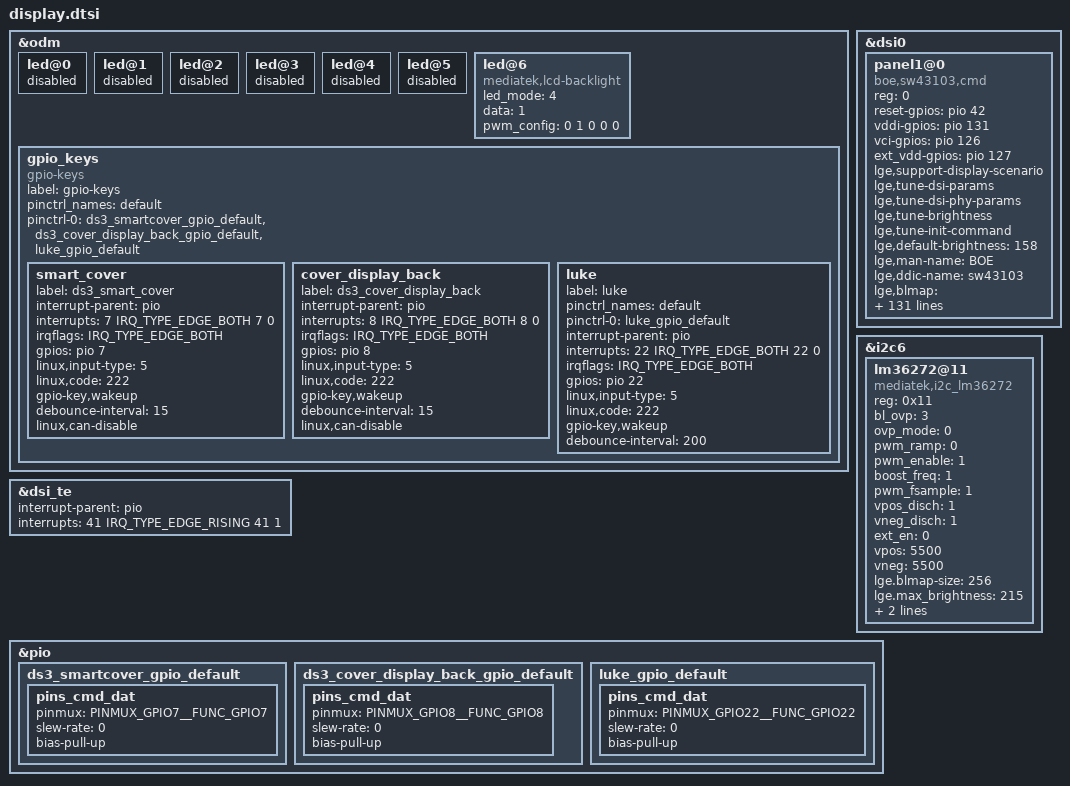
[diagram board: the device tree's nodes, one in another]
/*
 * Mediatek's mt6885 SoC device tree source
 *
 * Copyright (C) 2016 MediaTek Inc.
 *
 * This program is free software; you can redistribute it and/or modify
 * it under the terms of the GNU General Public License version 2 as
 * published by the Free Software Foundation.
 *
 * This program is distributed in the hope that it will be useful,
 * but WITHOUT ANY WARRANTY; without even the implied warranty of
 * MERCHANTABILITY or FITNESS FOR A PARTICULAR PURPOSE.
 * See http://www.gnu.org/licenses/gpl-2.0.html for more details.
 */

&odm {
	led@0 {
		status = "disabled";
	};
	led@1 {
		status = "disabled";
	};
	led@2 {
		status = "disabled";
	};
	led@3 {
		status = "disabled";
	};
	led@4 {
		status = "disabled";
	};
	led@5 {
		status = "disabled";
	};
	led@6 {
		compatible = "mediatek,lcd-backlight";
		led_mode = <4>;
		data = <1>;
		pwm_config = <0 1 0 0 0>;
	};
};

&dsi0 {
	status = "okay";
	#address-cells = <1>;
	#size-cells = <0>;
	panel1@0 {
		compatible = "boe,sw43103,cmd";
		reg = <0>;
		/*pm-enable-gpios = <&pio 41 0>;*/
		reset-gpios = <&pio 42 0>;
		vddi-gpios = <&pio 131 0>;
		vci-gpios = <&pio 126 0>;
		ext_vdd-gpios = <&pio 127 0>;
		pinctrl-names = "default";

		lge,support-display-scenario;

		lge,tune-dsi-params;
		lge,tune-dsi-phy-params;
		lge,tune-brightness;
		lge,tune-init-command;

		lge,default-brightness = <158>;
		lge,man-name = "BOE";
		lge,ddic-name = "sw43103";

		//lge,use-dim-ctrl;
		/* Brightness Map List */
		lge,blmap = <
			0
			5 5 5 5 5 5 5 5 5 5 6 6 7 7 8 8 9 9 10 10
			11 11 12 12 13 13 14 14 15 15 16 16 17 17 18 18 20 21 23 24
			26 28 29 31 32 34 36 37 39 40 42 44 45 47 48 50 52 53 55 56
			58 61 64 67 70 72 75 78 81 84 87 90 93 95 98 101 104 107 110 113
			116 120 125 130 127 132 136 141 146 151 155 160 165 170 174 179 184 189 193 198
			203 208 212 217 222 227 231 236 241 247 252 258 263 269 274 279 285 290 296 301
			307 312 317 323 328 334 339 344 350 355 361 366 372 377 385 392 400 408 415 423
			430 436 444 451 459 466 474 482 489 497 505 512 520 528 535 543 551 558 568 577
			586 596 605 614 623 632 642 651 660 669 679 688 697 706 715 725 734 743 752 761
			771 780 789 801 812 824 836 847 859 870 882 894 905 917 929 940 952 963 975 987
			998 1010 1022 1033 1045 1056 1068 1079 1090 1102 1113 1124 1135 1146 1158 1169 1180 1191 1202 1214
			1225 1236 1247 1258 1270 1281 1292 1303 1314 1326 1337 1348 1364 1379 1395 1410 1426 1441 1457 1472
			1488 1503 1519 1534 1550 1565 1581 1596 1612 1627 1643 1658 1674 1689 1705 1708 1710 1713 1715 1718
			1720 1723 1725 1728 1730 1733 1735 1738 1740 1743 1745 1748 1750 1753 1755 1758 1762 1765 1768 1772
			1775 1778 1782 1785 1788 1792 1795 1798 1802 1805 1808 1812 1815 1818 1822 1825 1828 1832 1835 1838
			1842 1845 1848 1852 1855 1858 1862 1865 1868 1872 1875 1878 1882 1885 1888 1892 1895 1898 1902 1905
			1908 1912 1915 1918 1922 1925 1928 1932 1935 1938 1942 1945 1948 1952 1955 1958 1962 1965 1968 1972
			1975 1978 1982 1985 1988 1992 1995 1998 2002 2005 2008 2011 2013 2016 2019 2022 2025 2027 2030 2033
			2036 2039 2041 2044 2047
		>;
		lge,blmap-ve = <
			0
			5 5 5 5 5 5 5 5 5 5 6 6 7 7 8 8 9 10 10 11
			11 12 13 13 14 14 15 15 16 17 17 18 18 19 19 20 22 24 26 28
			30 32 34 36 38 40 42 44 45 47 49 51 53 55 57 59 61 63 65 67
			69 73 76 80 83 87 91 94 98 101 105 108 112 116 119 123 126 130 134 137
			141 147 152 158 155 161 167 173 178 184 190 196 202 208 214 220 225 231 237 243
			249 255 261 267 272 278 284 290 297 305 312 319 326 334 341 348 355 363 370 377
			385 392 399 406 414 421 428 435 443 450 457 464 472 479 487 496 504 512 521 529
			538 545 553 562 570 578 587 595 603 612 620 628 637 645 653 662 670 679 688 701
			713 726 739 751 764 777 789 802 815 827 840 853 865 878 891 903 916 929 941 954
			967 979 992 1005 1018 1031 1044 1057 1070 1082 1095 1108 1121 1134 1147 1160 1173 1186 1199 1212
			1225 1237 1250 1263 1276 1289 1302 1316 1330 1344 1358 1371 1385 1399 1413 1427 1441 1455 1469 1482
			1496 1510 1524 1538 1552 1566 1580 1593 1607 1621 1635 1649 1666 1684 1701 1718 1736 1753 1770 1787
			1805 1822 1839 1857 1874 1891 1909 1926 1943 1960 1978 1995 2012 2030 2047 2047 2047 2047 2047 2047
			2047 2047 2047 2047 2047 2047 2047 2047 2047 2047 2047 2047 2047 2047 2047 2047 2047 2047 2047 2047
			2047 2047 2047 2047 2047 2047 2047 2047 2047 2047 2047 2047 2047 2047 2047 2047 2047 2047 2047 2047
			2047 2047 2047 2047 2047 2047 2047 2047 2047 2047 2047 2047 2047 2047 2047 2047 2047 2047 2047 2047
			2047 2047 2047 2047 2047 2047 2047 2047 2047 2047 2047 2047 2047 2047 2047 2047 2047 2047 2047 2047
			2047 2047 2047 2047 2047 2047 2047 2047 2047 2047 2047 2047 2047 2047 2047 2047 2047 2047 2047 2047
			2047 2047 2047 2047 2047
		>;
		lge,blmap-ex = <
			0
			16 16 16 16 16 16 16 16 16 25 35 44 53 62 72 81 90 99 109 118
			127 136 146 155 164 173 183 192 201 210 220 229 238 247 257 266 273 281 288 295
			303 310 317 325 332 339 347 354 361 369 376 383 391 398 405 413 420 427 435 442
			449 457 464 471 479 486 493 501 508 515 523 530 537 545 552 572 592 612 632 652
			672 692 712 732 752 772 792 812 832 852 872 892 912 932 952 972 992 1009 1026 1043
			1060 1076 1093 1110 1127 1144 1161 1178 1195 1212 1228 1245 1262 1279 1296 1310 1325 1339 1353 1368
			1382 1396 1411 1425 1439 1453 1468 1482 1496 1511 1525 1539 1554 1568 1568 1568 1568 1568 1568 1568
			1589 1611 1632 1653 1674 1696 1717 1738 1759 1781 1802 1823 1844 1866 1887 1908 1929 1951 1972 1972
			1972 1972 1972 1972 1972 1972 1972 1972 1972 1972 1972 1972 1972 1972 1972 1972 1972 1972 1972 1972
			1972 1972 1972 1972 1972 1972 1972 1972 1972 1972 1972 1972 1972 1972 1972 1972 1972 1972 1972 1972
			1972 1972 1972 1972 1972 1972 1972 1972 1972 1972 1972 1972 1972 1972 1972 1972 1972 1972 1972 1972
			1972 1972 1972 1972 1972 1972 1972 1972 1972 1972 1972 1972 1972 1972 1972 1972 1972 1972 1972 1972
			1972 1972 1972 1972 1972 1972 1972 1972 1972 1972 1972 1972 1972 1972 1972
		>;
		lge,blmap-hdr = <
			0
			5 5 5 5 5 5 5 5 5 5 6 6 7 7 8 8 9 9 10 10
			11 11 12 12 13 13 14 14 15 15 16 16 17 17 18 18 20 21 23 24
			26 28 29 31 32 34 36 37 39 40 42 44 45 47 48 50 52 53 55 56
			58 61 64 67 70 72 75 78 81 84 87 90 93 95 98 101 104 107 110 113
			116 120 125 130 127 132 136 141 146 151 155 160 165 170 174 179 184 189 193 198
			203 208 212 217 222 227 231 236 241 247 252 258 263 269 274 279 285 290 296 301
			307 312 317 323 328 334 339 344 350 355 361 366 372 377 385 392 400 408 415 423
			430 436 444 451 459 466 474 482 489 497 505 512 520 528 535 543 551 558 568 577
			586 596 605 614 623 632 642 651 660 669 679 688 697 706 715 725 734 743 752 761
			771 780 789 801 812 824 836 847 859 870 882 894 905 917 929 940 952 963 975 987
			998 1010 1022 1033 1045 1056 1068 1079 1090 1102 1113 1124 1135 1146 1158 1169 1180 1191 1202 1214
			1225 1236 1247 1258 1270 1281 1292 1303 1314 1326 1337 1348 1364 1379 1395 1410 1426 1441 1457 1472
			1488 1503 1519 1534 1550 1565 1581 1596 1612 1627 1643 1658 1674 1689 1705 1708 1710 1713 1715 1718
			1720 1723 1725 1728 1730 1733 1735 1738 1740 1743 1745 1748 1750 1753 1755 1758 1762 1765 1768 1772
			1775 1778 1782 1785 1788 1792 1795 1798 1802 1805 1808 1812 1815 1818 1822 1825 1828 1832 1835 1838
			1842 1845 1848 1852 1855 1858 1862 1865 1868 1872 1875 1878 1882 1885 1888 1892 1895 1898 1902 1905
			1908 1912 1915 1918 1922 1925 1928 1932 1935 1938 1942 1945 1948 1952 1955 1958 1962 1965 1968 1972
			1975 1978 1982 1985 1988 1992 1995 1998 2002 2005 2008 2011 2013 2016 2019 2022 2025 2027 2030 2033
			2036 2039 2041 2044 2047
		>;
		lge,blmap-hdr-daylight = <
			0
			5 5 5 5 5 5 5 5 5 5 6 6 7 7 8 8 9 9 10 10
			11 11 12 13 13 14 14 15 15 16 16 17 17 18 18 19 21 23 25 27
			29 31 33 35 37 39 41 43 44 46 48 50 52 54 56 58 60 62 64 66
			68 71 75 78 82 85 89 92 95 99 102 106 109 112 116 119 123 126 130 133
			136 142 147 153 150 155 161 166 172 177 183 188 193 199 204 210 215 221 226 232
			237 242 248 253 259 264 270 275 282 289 296 303 310 317 323 330 337 344 351 358
			365 372 379 386 393 400 407 413 420 427 434 441 448 455 463 471 480 488 496 504
			512 519 528 536 544 552 560 569 577 585 593 601 610 618 626 634 642 651 660 672
			684 696 708 720 733 745 757 769 781 793 805 817 829 841 853 865 878 890 902 914
			926 938 950 963 975 988 1001 1013 1026 1038 1051 1064 1076 1089 1102 1114 1127 1139 1152 1165
			1177 1190 1203 1215 1228 1240 1253 1267 1280 1294 1308 1321 1335 1348 1362 1376 1389 1403 1417 1430
			1444 1458 1471 1485 1499 1512 1526 1539 1553 1567 1580 1594 1614 1633 1653 1673 1692 1712 1732 1752
			1771 1791 1811 1830 1850 1870 1889 1909 1929 1949 1968 1988 2008 2027 2047 2047 2047 2047 2047 2047
			2047 2047 2047 2047 2047 2047 2047 2047 2047 2047 2047 2047 2047 2047 2047 2047 2047 2047 2047 2047
			2047 2047 2047 2047 2047 2047 2047 2047 2047 2047 2047 2047 2047 2047 2047 2047 2047 2047 2047 2047
			2047 2047 2047 2047 2047 2047 2047 2047 2047 2047 2047 2047 2047 2047 2047 2047 2047 2047 2047 2047
			2047 2047 2047 2047 2047 2047 2047 2047 2047 2047 2047 2047 2047 2047 2047 2047 2047 2047 2047 2047
			2047 2047 2047 2047 2047 2047 2047 2047 2047 2047 2047 2047 2047 2047 2047 2047 2047 2047 2047 2047
			2047 2047 2047 2047 2047
		>;
		lge,blmap-daylight = <
			0
			5 5 5 5 5 5 5 5 5 5 6 6 7 7 8 8 9 9 10 10
			11 11 12 13 13 14 14 15 15 16 16 17 17 18 18 19 21 23 25 27
			29 31 33 35 37 39 41 43 44 46 48 50 52 54 56 58 60 62 64 66
			68 71 75 78 82 85 89 92 95 99 102 106 109 112 116 119 123 126 130 133
			136 142 147 153 150 155 161 166 172 177 183 188 193 199 204 210 215 221 226 232
			237 242 248 253 259 264 270 275 282 289 296 303 310 317 323 330 337 344 351 358
			365 372 379 386 393 400 407 413 420 427 434 441 448 455 463 471 480 488 496 504
			512 519 528 536 544 552 560 569 577 585 593 601 610 618 626 634 642 651 660 672
			684 696 708 720 733 745 757 769 781 793 805 817 829 841 853 865 878 890 902 914
			926 938 950 963 975 988 1001 1013 1026 1038 1051 1064 1076 1089 1102 1114 1127 1139 1152 1165
			1177 1190 1203 1215 1228 1240 1253 1267 1280 1294 1308 1321 1335 1348 1362 1376 1389 1403 1417 1430
			1444 1458 1471 1485 1499 1512 1526 1539 1553 1567 1580 1594 1614 1633 1653 1673 1692 1712 1732 1752
			1771 1791 1811 1830 1850 1870 1889 1909 1929 1949 1968 1988 2008 2027 2047 2047 2047 2047 2047 2047
			2047 2047 2047 2047 2047 2047 2047 2047 2047 2047 2047 2047 2047 2047 2047 2047 2047 2047 2047 2047
			2047 2047 2047 2047 2047 2047 2047 2047 2047 2047 2047 2047 2047 2047 2047 2047 2047 2047 2047 2047
			2047 2047 2047 2047 2047 2047 2047 2047 2047 2047 2047 2047 2047 2047 2047 2047 2047 2047 2047 2047
			2047 2047 2047 2047 2047 2047 2047 2047 2047 2047 2047 2047 2047 2047 2047 2047 2047 2047 2047 2047
			2047 2047 2047 2047 2047 2047 2047 2047 2047 2047 2047 2047 2047 2047 2047 2047 2047 2047 2047 2047
			2047 2047 2047 2047 2047
		>;

		lge,mdss-dsi-nolp-command = [
			39 01 00 00 00 00 03 51 00 00 // Set 0 brightness
			05 01 00 00 00 00 01 13
			15 01 00 00 00 00 02 B0 A1
			39 01 00 00 3C 00 12 C1 88 48 60 0F 51 50 50 34 4F 5A 33 06 54 54 11 11 02 // AVDD 6.7V change
			15 01 00 00 00 00 02 B0 CA
		];
		lge,mdss-dsi-nolp-command-state = "dsi_lp_mode";
		lge,mdss-dsi-lp2-command = [
			15 01 00 00 00 00 02 B0 A1
			39 01 00 00 3C 00 12 C1 88 48 60 0F 51 50 50 34 4F 5A 33 06 54 54 08 11 02 // AVDD 5.8V change
			05 01 00 00 00 00 01 12
			15 01 00 00 00 00 02 B0 CA
		];
		lge,mdss-dsi-lp2-command-state = "dsi_lp_mode";

		lge,use-vr-lp-mode;
		lge,mdss-dsi-vr-lp-mode-on-command = [
			15 01 00 00 00 00 02 B0 A3
			39 01 00 00 00 00 08 B5 00 0B 00 3B 00 3B 10
			15 01 00 00 00 00 02 B0 CA
		];
		lge,mdss-dsi-vr-lp-mode-off-command = [
			15 01 00 00 00 00 02 B0 A3
			39 01 00 00 00 00 08 B5 00 3B 00 3B 00 3B 10
			15 01 00 00 00 00 02 B0 CA
		];
		lge,mdss-dsi-vr-lp-command-state = "dsi_lp_mode";
		lge,blmap-vr = < 0 165 >;

		lge,use-color-manager;
		lge,use-color-manager-oled;
		lge,color-manager-default-status = <1>;
		lge,mdss-dsi-color-manager-mode-table = <0 1>, <1 1>, <2 1>, <3 1>;
		lge,digital-gamma-absent;
		/* FP LHBM */
		lge,use-fp-lhbm;
		lge,mdss-dsi-fp-lhbm-ready-command = [
			15 01 00 00 00 00 02 53 20 // BC Dimming On
			39 01 00 00 00 00 03 51 06 A9 // Set max brightness
		];
		lge,mdss-dsi-fp-lhbm-ready-command-state = "dsi_hs_mode";

		lge,mdss-dsi-fp-lhbm-exit-command = [
			15 01 00 00 00 00 02 53 00 // BC Dimming Off
		];
		lge,mdss-dsi-fp-lhbm-exit-command-state = "dsi_hs_mode";

		lge,mdss-dsi-fp-lhbm-on-command = [
			39 01 00 00 00 00 03 51 06 A9 // Set max brightness
			39 01 00 00 00 00 0B 55 08 08 82 8B 1C 61 0A 90 04 00 //FPS ON, Set position
		];
		lge,mdss-dsi-fp-lhbm-on-command-state = "dsi_hs_mode";

		lge,mdss-dsi-fp-lhbm-off-command = [
			39 01 00 00 00 00 0B 55 08 00 82 8B 1C 61 0A 90 04 00 //FPS OFF
		];
		lge,mdss-dsi-fp-lhbm-off-command-state = "dsi_hs_mode";

		lge,mdss-dsi-fp-lhbm-aod-to-fps = [
			15 01 00 00 00 00 02 B0 A3
			39 01 00 00 00 00 0D B7 09 A1 00 09 A1 00 09 A1 00 09 A1 00 // AOD EM OFF
			39 01 00 00 00 00 03 51 00 00 // Set 0 brightness

			15 01 00 00 00 00 02 B0 A1
			39 01 00 00 00 00 12 C1 88 48 60 0F 51 50 50 34 4F 5A 33 06 54 54 11 11 02 // AVDD 6.7V change
			05 01 00 00 32 00 01 13 //Normal On
			15 01 00 00 00 00 02 B0 A3
			39 01 00 00 00 00 0D B7 45 41 60 27 51 50 08 A9 F8 09 A1 00 // AOD EM ON
			15 01 00 00 00 00 02 B0 CA
		];
		lge,mdss-dsi-fp-lhbm-aod-to-fps-state = "dsi_hs_mode";

		lge,mdss-dsi-fp-lhbm-fps-to-aod = [
			39 01 00 00 00 00 03 51 00 00 // Set 0 brightness
			15 01 00 00 00 00 02 B0 A1
			39 01 00 00 3C 00 12 C1 88 48 60 0F 51 50 50 34 4F 5A 33 06 54 54 08 11 02 // AVDD 5.8V change
			05 01 00 00 00 00 01 12 //AOD On
			15 01 00 00 00 00 02 B0 CA
		];
		lge,mdss-dsi-fp-lhbm-fps-to-aod-state = "dsi_hs_mode";

		lge,mdss-dsi-bl-set = [
			39 01 00 00 00 00 03 51 02 38 // Set 0 brightness
		];
		lge,mdss-dsi-bl-set-state = "dsi_hs_mode";

		/* Screen Color Control */
		lge,mdss-dsi-disp-ctrl-command-1 = [
			15 01 00 00 00 00 02 B0 A1
			15 01 00 00 00 00 02 53 00
			15 01 00 00 00 00 02 B0 CA
		];
		lge,mdss-dsi-disp-ctrl-command-1-state = "dsi_hs_mode";

		lge,mdss-dsi-wb-default-command = [
			15 01 00 00 00 00 02 B0 A4
			39 01 00 00 00 00 0B B4 00 03 05 AF 03 05 AF 03 05 AF
			39 01 00 00 00 00 1C B5 00 FF 94 1F AE 37 AE 1F 94 00 FB 94 1E AD 35 AB 1C 90 00 DD 8F 16 9F 24 97 04 75
			15 01 00 00 00 00 02 B0 CA
		];
		lge,mdss-dsi-wb-default-command-state = "dsi_hs_mode";

		lge,digital-gamma-cmds-dummy = [
			15 01 00 00 00 00 02 B0 A4
			39 01 00 00 00 00 0B B4 00 03 05 AF 03 05 AF 03 05 AF
			39 01 00 00 00 00 1C B5 00 FF 94 1F AE 37 AE 1F 94 00 FB 94 1E AD 35 AB 1C 90 00 DD 8F 16 9F 24 97 04 75
			15 01 00 00 00 00 02 B0 CA
		];
		lge,digital-gamma-cmds-dummy-command = "dsi_hs_mode";

		lge,mdss-dsi-saturation-command = [
			15 01 00 00 00 00 02 B0 A4
			39 01 00 00 00 00 0D B9 35 2D 2D 37 34 35 36 36 36 2D 35 33
			15 01 00 00 00 00 02 B0 CA
		];
		lge,mdss-dsi-saturation-command-state = "dsi_hs_mode";

		lge,mdss-dsi-hue-command = [
			15 01 00 00 00 00 02 B0 A4
			39 01 00 00 00 00 0D BB 80 5A 7B 95 65 70 96 90 90 90 83 72
			15 01 00 00 00 00 02 B0 CA
		];
		lge,mdss-dsi-hue-command-state = "dsi_hs_mode";

		lge,mdss-dsi-sharpness-command = [
			15 01 00 00 00 00 02 B0 A4
			39 01 00 00 00 00 0C B2 89 1F 1F 88 24 68 22 20 04 00 00
			15 01 00 00 00 00 02 B0 CA
		];
		lge,mdss-dsi-sharpness-command-state = "dsi_hs_mode";

		lge,mdss-dsi-cm-natural = [
			15 01 00 00 00 00 02 B0 A4
			39 01 00 00 00 00 0B B4 00 03 05 AF 03 05 AF 03 05 AF
			39 01 00 00 00 00 1C B5 00 FF 94 1F AE 37 AE 1F 94 00 FB 94 1E AD 35 AB 1C 90 00 DD 8F 16 9F 24 97 04 75
			39 01 00 00 00 00 0D B7 80 80 80 80 80 80 80 80 80 80 80 80
			39 01 00 00 00 00 0D B8 80 80 80 80 80 80 80 80 80 80 80 80
			39 01 00 00 00 00 0D B9 35 2D 2D 37 34 35 36 36 36 2D 35 33
			39 01 00 00 00 00 0D BA 80 80 80 80 88 80 80 80 80 80 80 7D
			39 01 00 00 00 00 0D BB 80 5A 7B 95 65 70 96 90 90 90 83 72
			15 01 00 00 00 00 02 B0 CA
		];
		lge,mdss-dsi-cm-natural-state = "dsi_hs_mode";

		lge,mdss-dsi-cm-vivid = [
			15 01 00 00 00 00 02 B0 A4
			39 01 00 00 00 00 0B B4 00 03 05 AF 03 05 AF 03 05 AF
			39 01 00 00 00 00 1C B5 00 FF 90 22 B3 37 AE 1F 90 00 FF 8E 19 AC 34 AE 23 96 00 FF 90 1E AE 30 A6 13 88
			39 01 00 00 00 00 0D B7 80 80 80 80 80 80 80 80 80 80 80 80
			39 01 00 00 00 00 0D B8 80 80 80 80 80 80 80 80 80 80 80 80
			39 01 00 00 00 00 0D B9 43 43 43 3D 38 3E 43 43 43 43 46 46
			39 01 00 00 00 00 0D BA 80 80 80 80 80 80 80 80 80 80 80 80
			39 01 00 00 00 00 0D BB 80 80 80 80 7A 80 80 80 80 80 80 80
			15 01 00 00 00 00 02 B0 CA
		];
		lge,mdss-dsi-cm-vivid-state = "dsi_hs_mode";

		lge,mdss-dsi-cm-cinema = [
			15 01 00 00 00 00 02 B0 A4
			39 01 00 00 00 00 0B B4 00 03 05 AF 03 05 AF 03 05 AB
			39 01 00 00 00 00 1C B5 00 FF A1 26 AF 38 AF 20 95 00 EC 90 18 AF 31 A7 17 80 00 B3 8D 12 9A 14 84 F7 65
			39 01 00 00 00 00 0D B7 80 80 80 80 80 80 80 80 80 80 80 80
			39 01 00 00 00 00 0D B8 80 80 80 80 89 80 80 80 80 80 80 80
			39 01 00 00 00 00 0D B9 39 3A 36 3A 3D 38 3D 3A 3A 3A 35 35
			39 01 00 00 00 00 0D BA 80 80 80 80 88 80 80 80 80 80 7D 7D
			39 01 00 00 00 00 0D BB 6A 77 85 8B 75 70 86 85 85 80 5D 6F
			15 01 00 00 00 00 02 B0 CA
		];
		lge,mdss-dsi-cm-cinema-state = "dsi_hs_mode";

		/* Video Enahnacement */
		lge,mdss-dsi-ve-on-command = [
			15 01 00 00 00 00 02 B0 A4
			39 01 00 00 00 00 0C B2 89 3F 2F 88 88 88 33 20 04 00 00
			39 01 00 00 00 00 07 B3 00 80 FF 88 08 93
			39 01 00 00 00 00 0D B7 80 80 80 80 80 80 80 80 80 80 80 80
			39 01 00 00 00 00 0D B8 80 80 80 80 80 80 80 80 80 80 80 80
			39 01 00 00 00 00 0D B9 46 46 46 43 38 43 46 46 46 46 46 46
			39 01 00 00 00 00 0D BA 80 80 80 80 80 80 80 80 80 80 80 80
			39 01 00 00 00 00 0D BB 80 80 80 80 7A 80 80 80 80 80 80 80
			15 01 00 00 00 00 02 B0 A1
			15 01 00 00 00 00 02 53 14
			39 01 00 00 00 00 02 55 18
			15 01 00 00 00 00 02 B0 CA
		];
		lge,mdss-dsi-ve-on-command-state = "dsi_hs_mode";

		lge,mdss-dsi-ve-off-command = [
			15 01 00 00 00 00 02 B0 A1
			15 01 00 00 00 00 02 53 00
			39 01 00 00 00 00 02 55 08
			15 01 00 00 00 00 02 B0 CA
		];
		lge,mdss-dsi-ve-off-command-state = "dsi_hs_mode";

		lge,use-irc-ctrl;
		lge,mdss-dsi-irc-command = [
			15 01 00 00 00 00 02 B0 A5
			39 01 00 00 00 00 08 B1 60 C0 00 00 00 10 FF
			15 01 00 00 00 00 02 B0 CA
		];
		lge,mdss-dsi-irc-command-state = "dsi_hs_mode";
		lge,use-ace-ctrl;
		lge,default-ace-mode = <0>;
		lge,mdss-dsi-ace-tune-command = [
			15 01 00 00 00 00 02 B0 A4
			39 01 00 00 00 00 0C B2 89 3F 2F 88 88 88 33 20 04 00 00
			39 01 00 00 00 00 07 B3 00 80 FF 88 08 93
			15 01 00 00 00 00 02 B0 A1
			15 01 00 00 00 00 02 53 14
			39 01 00 00 00 00 02 55 28
			15 01 00 00 00 00 02 B0 CA
		];

		lge,mdss-dsi-ace-restore-command = [
			15 01 00 00 00 00 02 B0 A1
			39 01 00 00 00 00 02 55 08
			15 01 00 00 00 00 02 B0 CA
		];

		lge,mdss-dsi-ace-command-state = "dsi_hs_mode";

		/* tc Perf */
		lge,use-tc-perf;
		lge,mdss-dsi-tc-perf-on-command = [
			15 01 00 00 00 00 02 B0 A3
			39 01 00 00 00 00 1F B6 90 00 A1 90 00 A1 71 B0 F1 63 60 41 45 0D 94 26 BD E4 27 61 40 18 05 9C 08 A9 F8 09 A1 00
			15 01 00 00 00 00 02 B0 CA
		];
		lge,mdss-dsi-tc-perf-on-command-state = "dsi_hs_mode";

		lge,mdss-dsi-tc-perf-off-command = [
			15 01 00 00 00 00 02 B0 A3
			39 01 00 00 00 00 1F B6 90 00 A1 80 F7 AA 71 B0 F1 63 60 41 45 0D 94 26 BD E4 27 61 40 18 05 9C 08 A9 F8 09 A1 00
			15 01 00 00 00 00 02 B0 CA
		];
		lge,mdss-dsi-tc-perf-off-command-state = "dsi_hs_mode";

		lge,mdss-dsi-br-enhance-on-command = [
			/* GIRC Weight 1-4 */
			15 01 00 00 00 00 02 B0 A5
			39 01 00 00 00 00 2E B2 55 54 00 00 55 50 00 01 55 EA CA 9D 7B 57 37 17 F7 DA BC 9E 7F 62 48 2F 15 D0 A1 7A 56 33 12 F2 D1 B1 92 72 55 38 1B 00 A5 74 4C 24 00
			39 01 00 00 00 00 2E B3 00 00 15 00 00 05 00 00 04 DF BF 9F 7F 60 41 22 05 00 75 46 1D F7 D3 B0 90 6E 4C 2E 0F 00 00 47 1A F1 C7 A2 80 60 3E 1D 00 00 00 29 F4
			39 01 00 00 00 00 2E B4 00 00 00 00 00 00 00 00 00 C8 A0 77 54 33 10 00 00 00 DE B6 8E 6A 45 25 06 00 00 00 C5 95 6B 45 23 01 00 00 00 A0 73 47 23 00 00 00 00
			39 01 00 00 00 00 24 B5 00 00 00 00 00 00 00 84 52 27 01 00 00 00 5D 35 0B 00 00 00 3E 1A 00 00 00 30 00 00 00 20 00 00 00 00 00
			15 01 00 00 00 00 02 B0 CA
		];
		lge,mdss-dsi-br-enhance-on-command-state = "dsi_hs_mode";

		lge,mdss-dsi-br-enhance-off-command = [
			/* GIRC Weight 1-4 */
			15 01 00 00 00 00 02 B0 A5
			39 01 00 00 00 00 2E B2 95 00 00 00 54 00 00 01 40 30 54 33 1A FF E7 CF B8 A2 8C 75 5E 49 36 23 10 59 36 19 FE E4 CC B4 9B 84 6D 55 3F 2A 14 00 39 15 F7 D9 BE
			39 01 00 00 00 00 2E B3 00 00 10 00 00 00 00 00 00 A6 8E 76 5E 47 30 19 04 00 15 F2 D4 B8 9D 83 6B 52 39 22 0B 00 00 F3 D2 B3 94 78 5F 47 2E 16 00 00 00 DD B5
			39 01 00 00 00 00 2E B4 00 00 00 00 00 00 00 00 00 95 77 58 3E 26 0C 00 00 00 A5 87 6A 4F 33 1C 04 00 00 00 92 6F 50 33 1A 01 00 00 00 77 55 35 1A 00 00 00 00
			39 01 00 00 00 00 24 B5 00 00 00 00 00 00 00 62 3D 1D 01 00 00 00 45 27 08 00 00 00 2E 13 00 00 00 24 00 00 00 01 00 00 00 00 00
			15 01 00 00 00 00 02 B0 CA
		];
		lge,mdss-dsi-br-enhance-off-command-state = "dsi_hs_mode";

		lge,mdss-dsi-ecc-on-command = [
			15 01 00 00 00 00 02 B0 A5
			39 01 00 00 00 00 02 D1 01 // ECC Enable
			15 01 00 00 00 00 02 B0 CA
		];
		lge,mdss-dsi-ecc-on-command-state = "dsi_hs_mode";

		lge,mdss-dsi-ecc-off-command = [
			15 01 00 00 00 00 02 B0 A5
			39 01 00 00 00 00 02 D1 00 // ECC Disable
			15 01 00 00 00 00 02 B0 CA
		];
		lge,mdss-dsi-ecc-off-command-state = "dsi_hs_mode";
	};
};

&dsi_te {
	interrupt-parent = <&pio>;
	interrupts = <41 IRQ_TYPE_EDGE_RISING 41 1>;
	status = "okay";
};

&i2c6 {
	#address-cells = <1>;
	#size-cells = <0>;
	lm36272@11 {
		compatible = "mediatek,i2c_lm36272";
		reg = <0x11>;
		status = "okay";

		bl_ovp = <3>; /* 0: 17V, 1: 21V, 2: 25V, 3: 29V */
		ovp_mode = <0>; /* OVP is report only */
		pwm_ramp = <0>; /* 0: No PWM ramp, 1: LED current ramps with changes in duty cycle */
		pwm_enable = <1>; /* 0: PWM Disable, 1: PWM Enable */
		boost_freq = <1>; /* boot switch frequency 0: 500kHz, 1: 1Mhz */
		pwm_fsample = <1>; /* PWM sampling frequency 0: 1Mhz, 1: 4Mhz */
		vpos_disch = <1>; /* 0: No pulldown, 1: pulldown */
		vneg_disch = <1>; /* 0: No pulldown, 1: pulldown */
		ext_en = <0>; /* 0: i2c mode, 1: external pin mode */
		vpos = <5500>;
		vneg = <5500>;

		lge.blmap-size = <256>;
		lge.max_brightness = <215>;
		lge.blmap = <
			50 50 50 50 50 50 50 50 50 50 50 50 50 50 50 50 					// 15
			50 50 50 50 50 50 50 50 50 50 50 50 50 50 50 50						// 31
			50 50 50 50 50 50 50 50 50 50 50 50 50 50 50 50						// 47
			50 50 50 50 50 50 50 50 50 50 50 50 50 50 50 50						// 63
			50 50 50 50 50 50 50 51 53 54 56 58 60 62 64 65						// 79
			67 69 71 73 75 77 79 81 83 85 87 90 92 94 96 98						// 95
			100 103 105 108 111 114 117 120 123 126 129 132 135 137 140 143		// 111
			146 148 151 154 157 159 162 165 168 171 175 179 183 187 191 195		// 127
			199 203 207 211 215 220 223 227 231 235 239 243 247 251 255 259		// 143
			263 267 271 275 279 283 287 291 295 311 311 311 311 315 320 325		// 159
			331 336 341 347 352 358 363 368 374 379 385 390 396 401 407 413		// 175
			418 424 429 435 441 446 452 458 465 472 479 486 493 500 507 514		// 191
			521 528 535 540 545 551 556 561 567 572 578 583 588 594 599 605		// 207
			614 623 632 641 650 660 669 678 687 696 705 715 721 728 734 741		// 223
			747 754 760 767 773 780 786 793 800 807 815 823 830 838 846 853		// 239
			861 869 876 884 892 900 911 923 935 947 958 970 982 994 1005 1017	// 255
		>;
	};
};

&odm {
	gpio_keys {
		compatible = "gpio-keys";
		label = "gpio-keys";
		status = "okay";
		pinctrl_names = "default";
		pinctrl-0 = <&ds3_smartcover_gpio_default &ds3_cover_display_back_gpio_default &luke_gpio_default>;
		smart_cover {
			label = "ds3_smart_cover";
			interrupt-parent = <&pio>;
			/* IRQF_ONESHOT			0x00002000 */
			/* IRQF_TRIGGER_FALLING		0x00000002 */
			/* IRQF_NO_SUSPEND		0x00004000 */
			interrupts = <7 IRQ_TYPE_EDGE_BOTH 7 0>;
			irqflags = <IRQ_TYPE_EDGE_BOTH>;
			gpios = <&pio 7 IRQ_TYPE_EDGE_BOTH>;
			linux,input-type = <5>;
			linux,code = <222>;
			gpio-key,wakeup;
			debounce-interval = <15>;
			linux,can-disable;
		};

		cover_display_back {
			label = "ds3_cover_display_back";
			interrupt-parent = <&pio>;
			/* IRQF_ONESHOT			0x00002000 */
			/* IRQF_TRIGGER_FALLING		0x00000002 */
			/* IRQF_NO_SUSPEND		0x00004000 */
			interrupts = <8 IRQ_TYPE_EDGE_BOTH 8 0>;
			irqflags = <IRQ_TYPE_EDGE_BOTH>;
			gpios = <&pio 8 IRQ_TYPE_EDGE_BOTH>;
			linux,input-type = <5>;
			linux,code = <222>;
			gpio-key,wakeup;
			debounce-interval = <15>;
			linux,can-disable;
		};

		luke {
			label = "luke";
			pinctrl_names = "default";
			pinctrl-0 = <&luke_gpio_default>;
			interrupt-parent = <&pio>;
			/* IRQF_ONESHOT			0x00002000 */
			/* IRQF_TRIGGER_FALLING		0x00000002 */
			/* IRQF_NO_SUSPEND		0x00004000 */
			interrupts = <22 IRQ_TYPE_EDGE_BOTH 22 0>;
			irqflags = <IRQ_TYPE_EDGE_BOTH>;
			gpios = <&pio 22 IRQ_TYPE_EDGE_BOTH>;
			linux,input-type = <5>;
			linux,code = <222>;
			gpio-key,wakeup;
			debounce-interval = <200>;
		};
	};
};

&pio {
	ds3_smartcover_gpio_default: ds3_smartcover_gpio_default {
		pins_cmd_dat {
			pinmux = <PINMUX_GPIO7__FUNC_GPIO7>;
			slew-rate = <0>;
			bias-pull-up;
		};
	};

	ds3_cover_display_back_gpio_default: ds3_cover_display_back_gpio_default {
		pins_cmd_dat {
			pinmux = <PINMUX_GPIO8__FUNC_GPIO8>;
			slew-rate = <0>;
			bias-pull-up;
		};
	};

	luke_gpio_default: luke_gpio_default {
		pins_cmd_dat {
			pinmux = <PINMUX_GPIO22__FUNC_GPIO22>;
			slew-rate = <0>;
			bias-pull-up;
		};
	};
};

/*End of this file, DO NOT ADD ANYTHING HERE*/
